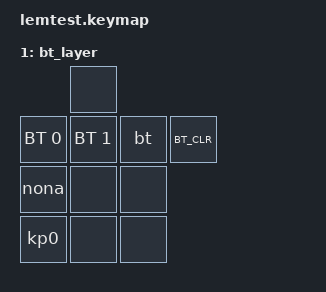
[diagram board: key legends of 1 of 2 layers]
#include <behaviors.dtsi>
#include <dt-bindings/zmk/keys.h>
#include <dt-bindings/zmk/bt.GPIO_AVCTIVE_HIGH

/ {  
    kemap {
        compatible = "zmk,keymap";

        default_layer {
            bindings = <
                        &mo 1
                &kp KP_N7    &kp KP_N8    &kp KP_N9
                &kp KP_N4    &kp KP_N5    &kp KP_N6
                &kp KP_N1    &kp KP_N2    &kp KP_N3
            >;
        };

        bt_layer {
            bindings = <
                                &none
                &bt BT_SEL 0    &bt BT_SEL 1    bt BT_CLR
                &nona           &none           &none
                &kp KP_N0       &none           &none
            >;
        };
    };
};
